AUTOSAR XML (schema 00046)
package /Runnables_LAB1
  sender receiver interface SRI_Throttle
    data Throttle_CMD: type=uint32
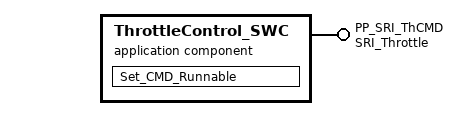
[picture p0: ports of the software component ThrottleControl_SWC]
  application sw component type ThrottleControl_SWC
    provide port PP_SRI_ThCMD: provided-interface=SRI_Throttle
    behavior ThrottleController_Beh
      runnable Set_CMD_Runnable: symbol=Set_CMD
        data-write-access:
          access CMD_Data: accessed-variable=PP_SRI_ThCMD.Throttle_CMD
